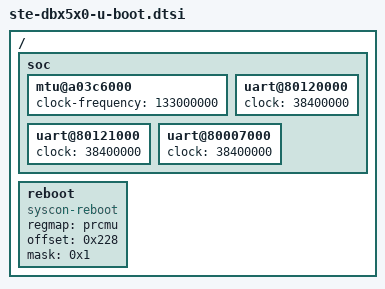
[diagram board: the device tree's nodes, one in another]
// SPDX-License-Identifier: GPL-2.0-or-later

#include "skeleton.dtsi"
#include "ste-dbx5x0.dtsi"

/ {
	soc {
		/* FIXME: Remove this when clk driver is implemented */
		mtu@a03c6000 {
			clock-frequency = <133000000>;
		};
		uart@80120000 {
			clock = <38400000>;
		};
		uart@80121000 {
			clock = <38400000>;
		};
		uart@80007000 {
			clock = <38400000>;
		};
	};

	reboot {
		compatible = "syscon-reboot";
		regmap = <&prcmu>;
		offset = <0x228>; /* PRCM_APE_SOFTRST */
		mask = <0x1>;
	};
};
